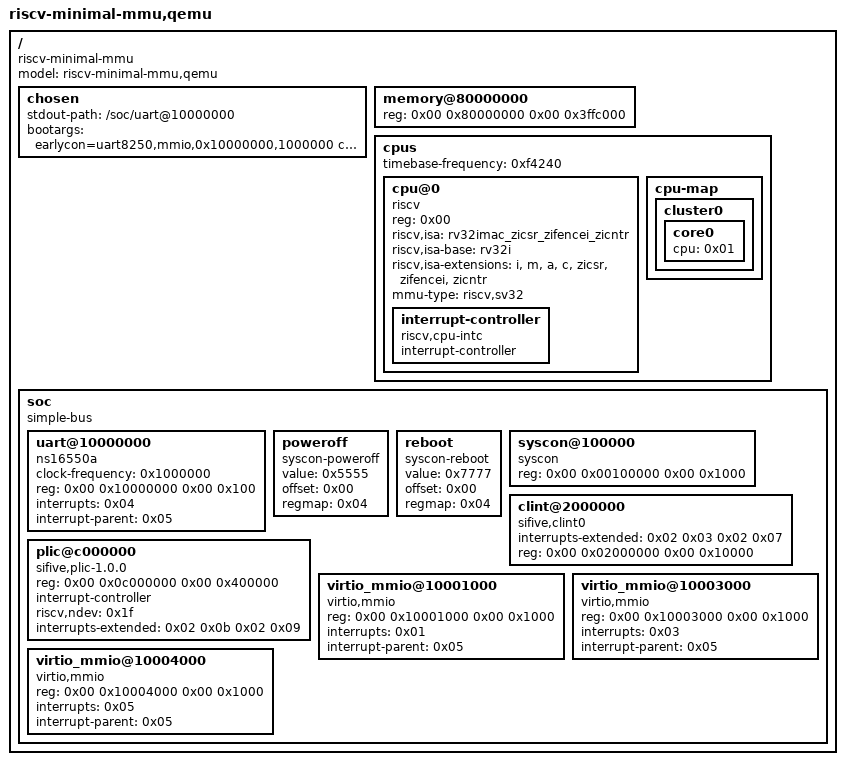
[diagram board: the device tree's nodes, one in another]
/*
 * Copyright Marc Ketel
 * SPDX-License-Identifier: Apache-2.0
 */

/dts-v1/;

/ {
    #address-cells = <0x02>;
    #size-cells = <0x02>;
    compatible = "riscv-minimal-mmu";
    model = "riscv-minimal-mmu,qemu";

    chosen {
        /* U-Boot binds the ns16550 console from this path before relocation. */
        stdout-path = "/soc/uart@10000000";
        /* Keep this PARTUUID in sync with configs/genimage-mmu.cfg in RISC-V-emulator-Linux. */
        bootargs = "earlycon=uart8250,mmio,0x10000000,1000000 console=ttyS0 root=PARTUUID=6f3d2a1e-9c4b-4e7a-8b1d-2c5e7f9a0b3c rw rootfstype=ext4";
    };

    memory@80000000 {
        device_type = "memory";
        reg = <0x00 0x80000000 0x00 0x3ffc000>;
    };

    cpus {
        #address-cells = <0x01>;
        #size-cells = <0x00>;
        timebase-frequency = <0xf4240>;

        cpu@0 {
            phandle = <0x01>;
            device_type = "cpu";
            reg = <0x00>;
            status = "okay";
            compatible = "riscv";
            riscv,isa = "rv32imac_zicsr_zifencei_zicntr";
            riscv,isa-base = "rv32i";
            riscv,isa-extensions = "i", "m", "a", "c", "zicsr", "zifencei", "zicntr";
            mmu-type = "riscv,sv32";

            interrupt-controller {
                #interrupt-cells = <0x01>;
                interrupt-controller;
                compatible = "riscv,cpu-intc";
                phandle = <0x02>;
            };
        };

        cpu-map {
            cluster0 {
                core0 {
                    cpu = <0x01>;
                };
            };
        };
    };

    soc {
        #address-cells = <0x02>;
        #size-cells = <0x02>;
        compatible = "simple-bus";
        ranges;

        uart@10000000 {
            clock-frequency = <0x1000000>;
            reg = <0x00 0x10000000 0x00 0x100>;
            compatible = "ns16550a";
            interrupts = <0x04>;
            interrupt-parent = <0x05>;
        };

        poweroff {
            value = <0x5555>;
            offset = <0x00>;
            regmap = <0x04>;
            compatible = "syscon-poweroff";
        };

        reboot {
            value = <0x7777>;
            offset = <0x00>;
            regmap = <0x04>;
            compatible = "syscon-reboot";
        };

        syscon@100000 {
            phandle = <0x04>;
            reg = <0x00 0x00100000 0x00 0x1000>;
            compatible = "syscon";
        };

        clint@2000000 {
            interrupts-extended = <0x02 0x03 0x02 0x07>;
            reg = <0x00 0x02000000 0x00 0x10000>;
            compatible = "sifive,clint0\0riscv,clint0";
        };

        plic@c000000 {
            compatible = "sifive,plic-1.0.0";
            reg = <0x00 0x0c000000 0x00 0x400000>;
            #interrupt-cells = <0x01>;
            interrupt-controller;
            riscv,ndev = <0x1f>;
            interrupts-extended = <0x02 0x0b 0x02 0x09>;
            phandle = <0x05>;
        };

        virtio_mmio@10001000 {
            compatible = "virtio,mmio";
            reg = <0x00 0x10001000 0x00 0x1000>;
            interrupts = <0x01>;
            interrupt-parent = <0x05>;
        };

        virtio_mmio@10003000 {
            compatible = "virtio,mmio";
            reg = <0x00 0x10003000 0x00 0x1000>;
            interrupts = <0x03>;
            interrupt-parent = <0x05>;
        };

        virtio_mmio@10004000 {
            compatible = "virtio,mmio";
            reg = <0x00 0x10004000 0x00 0x1000>;
            interrupts = <0x05>;
            interrupt-parent = <0x05>;
        };
    };
};
